# R7FS3A17 register map
Vendor: Renesas; Series: S3; File version: 1.2
CPU: CM4 r0p1, little endian, MPU, FPU, VTOR, 4 interrupt priority bits
Registers are 8-bit, read-write, reset 0x0 unless marked. A register's access mark holds for its fields unless they carry their own. Offsets are from the block's base; [hi:lo] are bit positions; {n}, {i} and the like mark numbered series.

## QSPI — Quad-SPI
Base 0x64000000
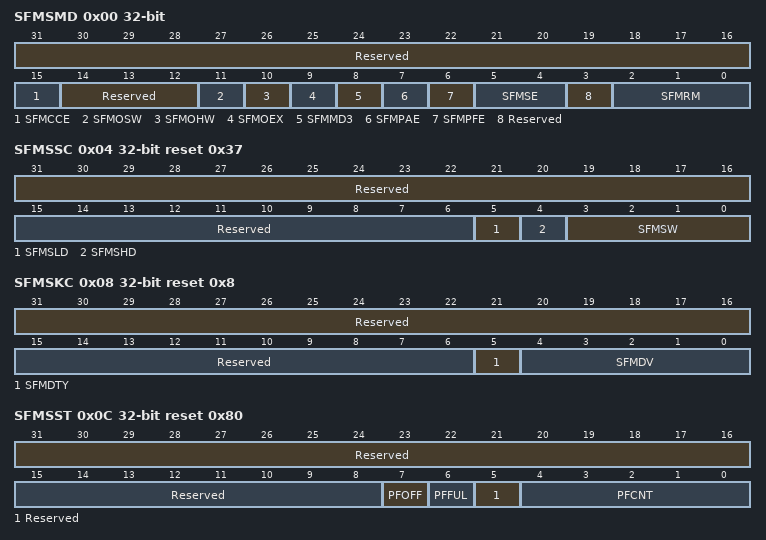
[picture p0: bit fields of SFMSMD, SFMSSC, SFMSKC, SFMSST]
0x00 SFMSMD 32-bit — Transfer Mode Control Register
  [31:16] Reserved — These bits are read as 0000000000000000. The write value should be 0000000000000000.
  [15] SFMCCE — Read instruction code selection.
    0=Default instruction code set for each instruction; 1=Instruction code written in the SFMSIC register
  [14:12] Reserved — These bits are read as 000. The write value should be 000.
  [11] SFMOSW — Setup time adjustment for serial transmission
    0=Does not extend the low-level width of SCK at transmission time; 1=Extends the low-level width of SCK by 1*PCLKA at transmission time
  [10] SFMOHW — Hold time adjustment for serial transmission
    0=Does not extend the high-level width of SCK at transmission time; 1=Extends the high-level width of SCK by 1*PCLKA at transmission time
  [9] SFMOEX — Extension of the I/O buffer output enable signal for the serial interface
    0=Does not extend the output enable signal; 1=Extends the output enable signal by 1*QSPCLK
  [8] SFMMD3 — SPI mode selection. An initial value is determined by input to CFGMD3.
    0=SPI mode 0; 1=SPI mode 3
  [7] SFMPAE — Selection of the function for stopping prefetch at locations other than on byte boundaries
    0=Disables prefetch stopping at locations other than on byte boundaries; 1=Enables prefetch stopping at locations other than on byte boundaries
  [6] SFMPFE — Selection of the prefetch function
    0=Disables prefetch; 1=Enables prefetch
  [5:4] SFMSE — Selection of the prefetch function
    0=Does not extend QSSL; 1=Extends QSSL by 33*QSPCLK; 2=Extends QSSL by 129*QSPCLK; 3=Extends QSSL infinitely
  [3] Reserved — This bit is read as 0. The write value should be 0.
  [2:0] SFMRM — Serial interface read mode selection
    0=Standard Read; 1=Fast Read; 2=Fast Read Dual Output; 3=Fast Read Dual I/O; 4=Fast Read Quad Output; 5=Fast Read Quad I/O; 6=Setting prohibited; 7=Setting prohibited
0x04 SFMSSC 32-bit reset 0x37 — Chip Selection Control Register
  [31:16] Reserved — These bits are read as 0000000000000000. The write value should be 0000000000000000.
  [15:6] Reserved — These bits are read as 0000000000. The write value should be 0000000000.
  [5] SFMSLD — QSSL signal output timing selection
    0=Outputs QSSL 0.5*SCK before the first rising edge of QSPCLK; 1=Outputs QSSL 1.5*SCK before the first rising edge of QSPCLK
  [4] SFMSHD — QSSL signal release timing selection
    0=Releases QSSL 0.5*SCK after the last rising edge of QSPCLK; 1=Releases QSSL 1.5*SCK after the last rising edge of QSPCLK
  [3:0] SFMSW — Selection of a minimum high-level width of the QSSL signal
    {v}={v+1} x QSPCLK (v=0..15)
0x08 SFMSKC 32-bit reset 0x8 — Clock Control Register
  [31:16] Reserved — These bits are read as 0000000000000000. The write value should be 0000000000000000.
  [15:6] Reserved — These bits are read as 0000000000. The write value should be 0000000000.
  [5] SFMDTY — Selection of a duty ratio correction function for the SCK signal
    0=Serial interface reference cycle selection (* Pay attention to the irregularity.); 1=Delays the rising of the SCK signal by 0.5*PCLKA.(* Valid with PCLKA multiplied by an odd number)
  [4:0] SFMDV — Serial interface reference cycle selection (* Pay attention to the irregularity.) NOTE: When PCLKA multiplied by an odd number is selected, the high-level width of the SCK signal is longer than the low-level width by 1 x PCLKA before duty ratio correction.
    16=18 x PCLKA; 17=20 x PCLKA; 18=22 x PCLKA; 19=24 x PCLKA; 20=26 x PCLKA; 21=28 x PCLKA; 22=30 x PCLKA; 23=32 x PCLKA; 24=34 x PCLKA; 25=36 x PCLKA; 26=38 x PCLKA; 27=40 x PCLKA; 28=42 x PCLKA; 29=44 x PCLKA; 30=46 x PCLKA; 31=48 x PCLKA; other=others (( SFMDV + 2 ) x PCLKA)
0x0C SFMSST 32-bit ro reset 0x80 — Status Register
  [31:16] Reserved — These bits are read as 0000000000000000.
  [15:8] Reserved — These bits are read as 00000000.
  [7] PFOFF — Prefetch function operation state
    0=The prefetch function is operating; 1=The prefetch function is not enabled or is not operating
  [6] PFFUL — Prefetch buffer state
    0=The prefetch buffer has a free space; 1=The prefetch buffer is full
  [5] Reserved — This bit is read as 0.
  [4:0] PFCNT — Number of bytes of prefetched data Range: 00000 - 10010 (No combination other than the above is available.)
    0=Nodata has been prefetched; other=others (Data of (PFCNT) bytes hs been prefetched.)
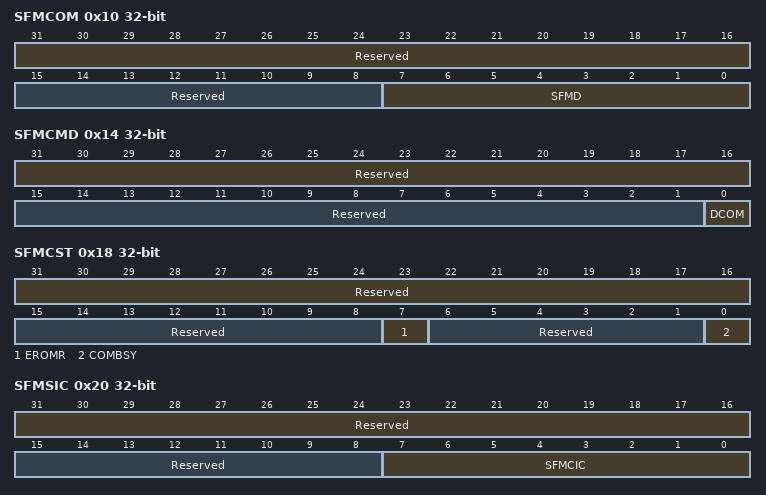
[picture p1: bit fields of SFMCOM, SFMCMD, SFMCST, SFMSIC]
0x10 SFMCOM 32-bit (reset mask 0xFFFFFF00) — Communication Port Register
  [31:16] Reserved — These bits are read as 0000000000000000. The write value should be 0000000000000000.
  [15:8] Reserved — These bits are read as 00000000. The write value should be 00000000.
  [7:0] SFMD — Port for direct communication with the SPI bus. Input/output to and from this port is converted to an SPI bus cycle. This port is accessible in the direct communication mode (DCOM=1) only. Access to this port is ignored in the ROM access mode.
0x14 SFMCMD 32-bit — Communication Mode Control Register
  [31:16] Reserved — These bits are read as 0000000000000000. The write value should be 0000000000000000.
  [15:1] Reserved — These bits are read as 000000000000000. The write value should be 000000000000000.
  [0] DCOM — Selection of a mode of communication with the SPI bus
    0=ROM access mode; 1=Direct communication mode
0x18 SFMCST 32-bit — Communication Status Register
  [31:16] Reserved — These bits are read as 0000000000000000. The write value should be 0000000000000000.
  [15:8] Reserved — These bits are read as 00000000. The write value should be 00000000.
  [7] EROMR write-0-clears read-modifies — Status of ROM access detection in the direct communication mode NOTE: Writing of 0 only is possible. Writing of 1 is ignored.
    0=ROM access is not detected in direct communication mode; 1=ROM access is detected in direct communication mode
  [6:1] Reserved — These bits are read as 000000. The write value should be 000000.
  [0] COMBSY ro — SPI bus cycle completion state in direct communication
    0=There is no serial transfer being processed; 1=There is a serial transfer being processed
0x20 SFMSIC 32-bit — Instruction Code Register
  [31:16] Reserved — These bits are read as 0000000000000000. The write value should be 0000000000000000.
  [15:8] Reserved — These bits are read as 00000000. The write value should be 00000000.
  [7:0] SFMCIC — Serial ROM instruction code to substitute
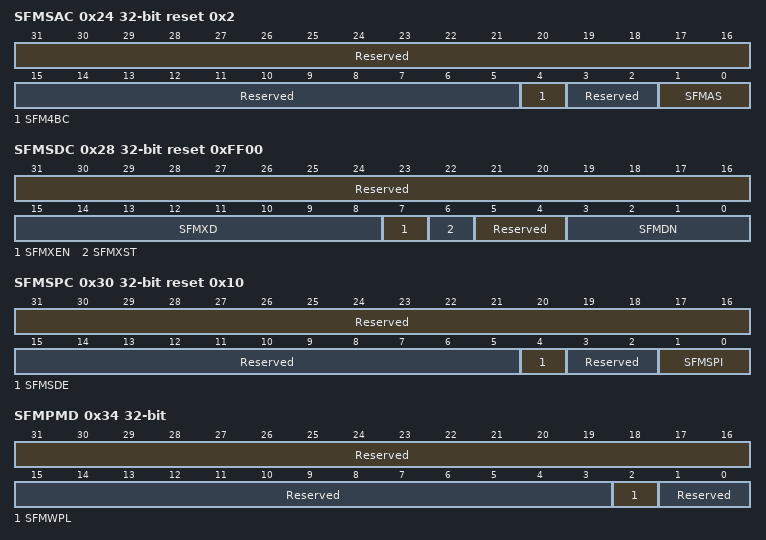
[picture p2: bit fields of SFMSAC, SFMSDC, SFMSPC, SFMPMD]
0x24 SFMSAC 32-bit reset 0x2 — Address Mode Control Register
  [31:16] Reserved — These bits are read as 0000000000000000. The write value should be 0000000000000000.
  [15:5] Reserved — These bits are read as 00000000000. The write value should be 00000000000.
  [4] SFM4BC — Selection of a default instruction code, when Serial Interface address width is selected 4 bytes.
    0=Does not use 4 Byte address read Instruction code; 1=Use 4 Byte address read Instruction code
  [3:2] Reserved — These bits are read as 00. The write value should be 00.
  [1:0] SFMAS — Selection the number of address bits of the serial interface
    0=1byte; 1=2bytes; 2=3bytes; 3=4 bytes
0x28 SFMSDC 32-bit reset 0xFF00 — Dummy Cycle Control Register
  [31:16] Reserved — These bits are read as 0000000000000000. The write value should be 0000000000000000.
  [15:8] SFMXD — Mode data for serial ROM. (Control XIP mode)
    0=XIP mode is prohibited; 1=XIP mode is permitted
  [7] SFMXEN — XIP mode permission
    0=XIP mode is prohibited; 1=XIP mode is permitted
  [6] SFMXST ro — XIP mode status
    0=Normal (non-XIP) mode is operating; 1=XIP mode is operating
  [5:4] Reserved — These bits are read as 00. The write value should be 00.
  [3:0] SFMDN — Selection of the number of dummy cycles of Fast Read instructions
    0=Default dummy cycles of each instruction; other=others (( SFMDN + 2 ) x SCK)
0x30 SFMSPC 32-bit reset 0x10 — SPI Protocol Control Register
  [31:16] Reserved — These bits are read as 0000000000000000. The write value should be 0000000000000000.
  [15:5] Reserved — These bits are read as 00000000000. The write value should be 00000000000.
  [4] SFMSDE — Selection of the minimum time of input output switch, when Dual SPI protocol or Quad SPI protocol is selected.
    0=Does not allocate minimum switch time; 1=Allocate the minimum switch time equivalent to 1*QSPXLK
  [3:2] Reserved — These bits are read as 00. The write value should be 00.
  [1:0] SFMSPI — Selection of SPI protocol NOTE: Serial ROM's SPI protocol is required to be set by software separately.
    0=Extended SPI protocol; 1=Dual SPI protocol; 2=Quad SPI protocol; 3=Setting prohibited
0x34 SFMPMD 32-bit — Port Control Register
  [31:16] Reserved — These bits are read as 0000000000000000. The write value should be 0000000000000000.
  [15:3] Reserved — These bits are read as 0000000000000. The write value should be 0000000000000.
  [2] SFMWPL — Specify level of WP pin
    0=Low level; 1=High level
  [1:0] Reserved — These bits are read as 00. The write value should be 00.
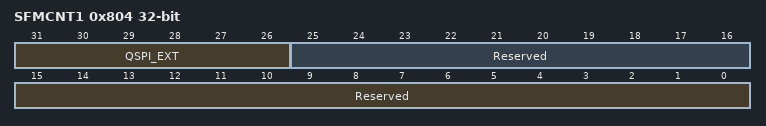
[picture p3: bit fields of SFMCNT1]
0x804 SFMCNT1 32-bit — External QSPI Address Register 1
  [31:26] QSPI_EXT — BANK Switching Address When accessing from 0x6000_0000 to 0x63FF_FFFF, Addres bus is Set QSPI_EXT[5:0] to high-order 6bits of SHADDR[31:0] NOTE: Setting 6'h3F is prihibited.
  [25:16] Reserved — These bits are read as 0000000000. The write value should be 0000000000.
  [15:0] Reserved — These bits are read as 0000000000000000. The write value should be 0000000000000000.
